# ATUC256L3U device description
Architecture: AVR32_UC3; Family: AVR UC3
Registers are 32-bit, read-write, reset 0x0 unless marked. A register's access mark holds for its fields unless they carry their own. Offsets are from the block's base; [hi:lo] are bit positions; {n}, {i} and the like mark numbered series; 'fields as' and 'values as' point back to an identical list.

## INTC — Interrupt Controller
Instances: INTC 0xffff1000
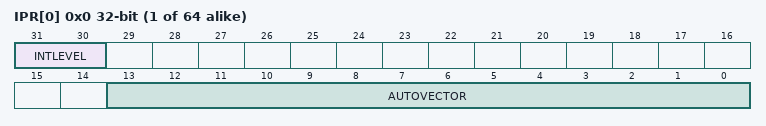
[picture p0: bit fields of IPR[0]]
{0x0+4i} IPR[{i}] (i=0..63) — Interrupt Priority Register
  [31:30] INTLEVEL — Interrupt Level
    {v}=INT{v} (v=0..3)
  [13:0] AUTOVECTOR — Handler offset
{0x100+4i} IRR[{i}] (i=0..63) ro — Interrupt Request Register
{0x200+4i} ICR[{i}] (i=0..3) ro — Interrupt Cause Register
  [5:0] CAUSE — Cause Group Number

## ABDACB — Audio Bitstream DAC
Instances: ABDACB 0xffff7400
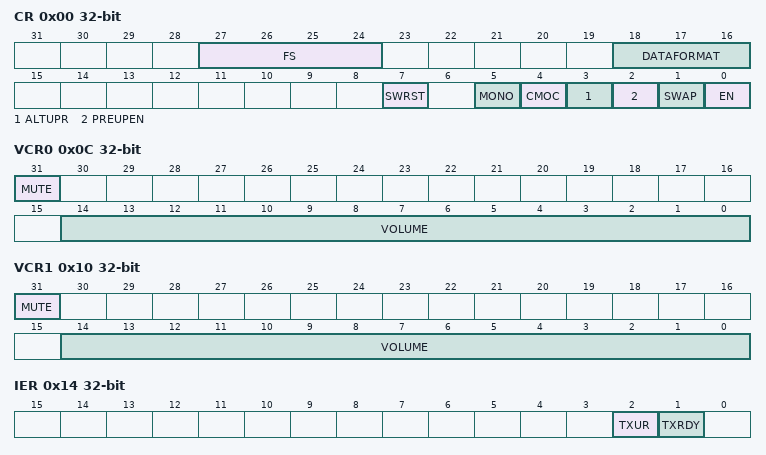
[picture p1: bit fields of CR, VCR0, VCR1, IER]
0x00 CR — Control Register
  [27:24] FS — Sampling frequency
  [18:16] DATAFORMAT — Data word format
  [7] SWRST — Software reset
  [5] MONO — Mono mode
  [4] CMOC — Common mode offset control
  [3] ALTUPR — Alternative up-sampling ratio
  [2] PREUPEN — Pre-upsampler enable
  [1] SWAP — Swap Channels
  [0] EN — Enable Audio DAC.
0x04 SDR0 — Sample Data Register 0
  [31:0] DATA
0x08 SDR1 — Sample Data Register 1
  [31:0] DATA
0x0C VCR0 — Volume Control Register 0
  [31] MUTE
  [14:0] VOLUME — Volume setting
0x10 VCR1 — Volume Control Register 1
  [31] MUTE
  [14:0] VOLUME — Volume setting
0x14 IER wo reset not defined — Interrupt Enable Register
  [2] TXUR — Underrun Interrupt Enable
  [1] TXRDY — TX Ready Interrupt Enable
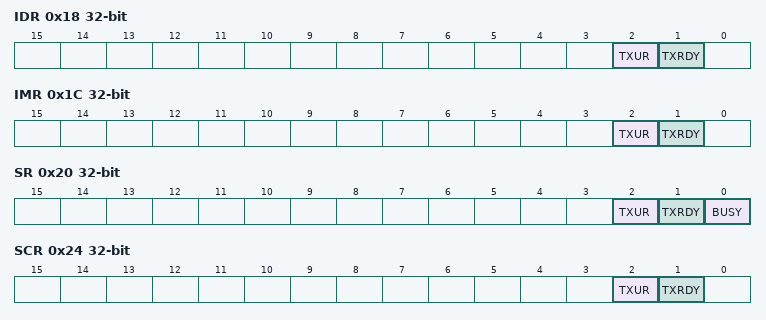
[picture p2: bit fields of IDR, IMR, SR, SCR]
0x18 IDR wo reset not defined — Interupt Disable Register
  [2] TXUR — Underrun Interrupt Disable
  [1] TXRDY — TX Ready Interrupt Disable
0x1C IMR ro — Interrupt Mask Register
  [2] TXUR — Underrun Interrupt Mask
  [1] TXRDY — TX Ready Interrupt Mask
0x20 SR ro — Status Register
  [2] TXUR — TX underrun
  [1] TXRDY — TX ready
  [0] BUSY
0x24 SCR wo reset not defined — Status Clear Register
  [2] TXUR — Underrun Interrupt Clear
  [1] TXRDY — TX Ready Interrupt Clear
0x28 PARAMETER ro
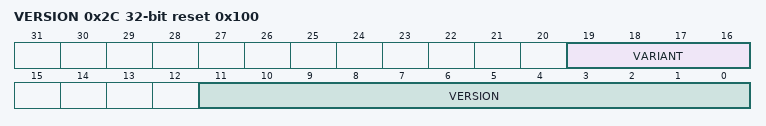
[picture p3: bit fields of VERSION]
0x2C VERSION ro reset 0x100
  [19:16] VARIANT, [11:0] VERSION

## ACIFB — Analog Comparator Interface
Instances: ACIFB 0xffff6400
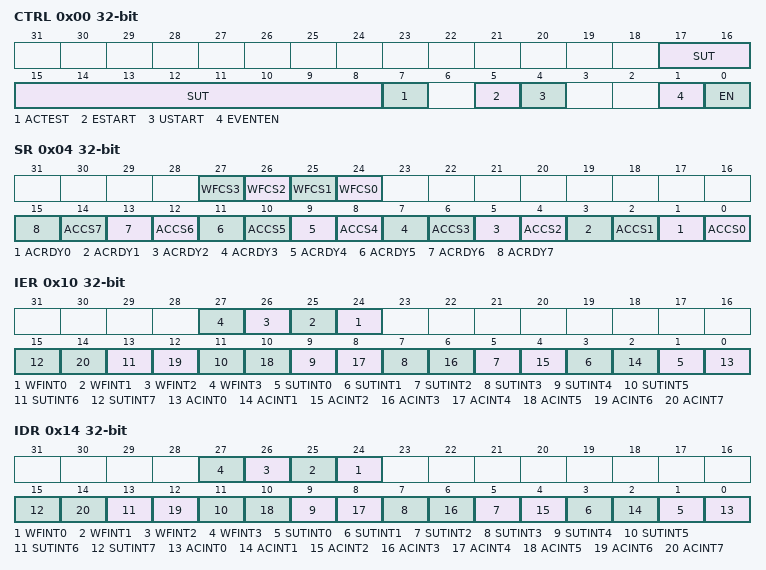
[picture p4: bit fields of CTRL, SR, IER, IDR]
0x00 CTRL — Control Register
  [17:8] SUT, [7] ACTEST, [5] ESTART, [4] USTART, [1] EVENTEN, [0] EN
0x04 SR ro — Status Register
  [n+24] WFCS{n} (n=0..3), [2n+1] ACRDY{n} (n=0..7), [2n] ACCS{n} (n=0..7)
0x10 IER wo — Interrupt Enable Register
  [n+24] WFINT{n} (n=0..3), [2n+1] SUTINT{n} (n=0..7), [2n] ACINT{n} (n=0..7)
0x14 IDR wo — Interrupt Disable Register
  fields as IER
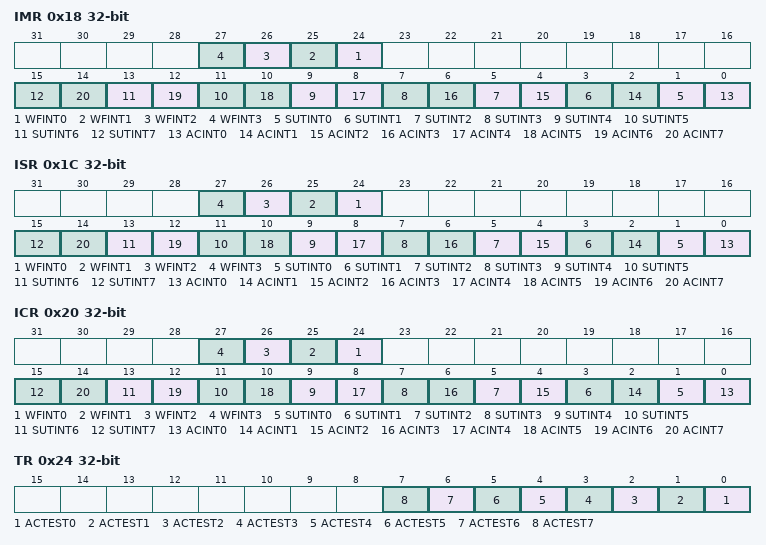
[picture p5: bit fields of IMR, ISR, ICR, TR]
0x18 IMR ro — Interrupt Mask Register
  fields as IER
0x1C ISR ro — Interrupt Status Register
  fields as IER
0x20 ICR wo — Interrupt Status Clear Register
  fields as IER
0x24 TR — Test Register
  [n] ACTEST{n} (n=0..7)
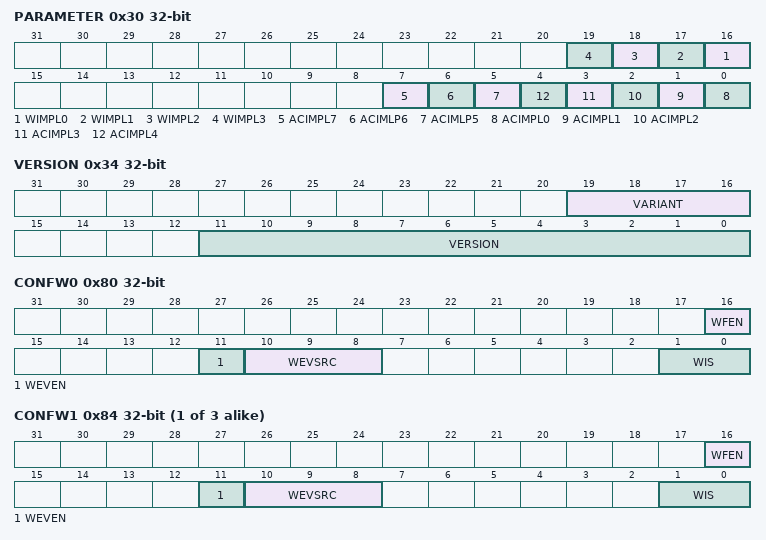
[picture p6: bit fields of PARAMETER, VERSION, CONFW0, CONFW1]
0x30 PARAMETER ro
  [n+16] WIMPL{n} (n=0..3), [7] ACIMPL7, [6] ACIMLP6, [5] ACIMLP5, [n] ACIMPL{n} (n=0..4)
0x34 VERSION ro reset not defined
  [19:16] VARIANT, [11:0] VERSION
0x80 CONFW0 — Window configuration Register
  [16] WFEN, [11] WEVEN, [10:8] WEVSRC, [1:0] WIS
{0x80+4i} CONFW{i} (i=1..3) — Window Configuration Register
  [16] WFEN, [11] WEVEN, [10:8] WEVSRC, [1:0] WIS
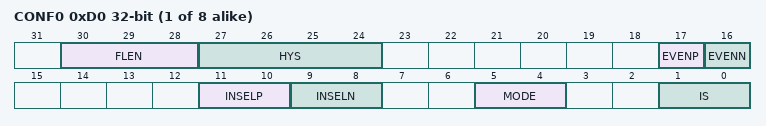
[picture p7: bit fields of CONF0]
{0xD0+4i} CONF{i} (i=0..7) — AC Configuration Register
  [30:28] FLEN, [27:24] HYS, [17] EVENP, [16] EVENN, [11:10] INSELP, [9:8] INSELN, [5:4] MODE, [1:0] IS

## ADCIFB — ADC Interface
Instances: ADCIFB 0xffff6000
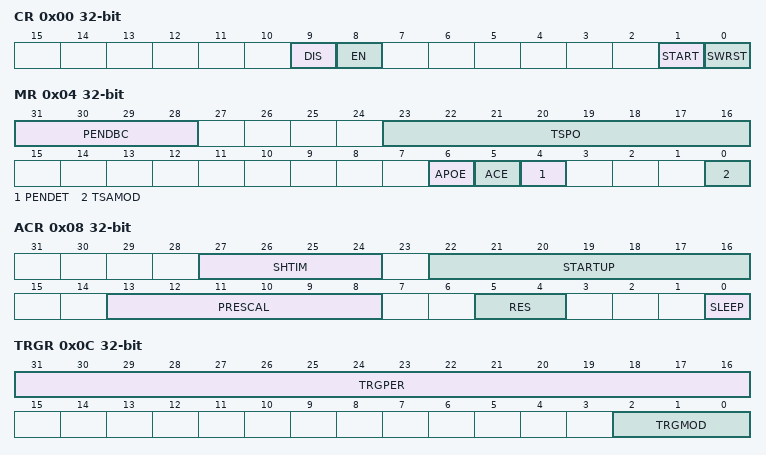
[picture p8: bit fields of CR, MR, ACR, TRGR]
0x00 CR wo reset not defined — Control Register
  [9] DIS — ADCIFB Disable
  [8] EN — ADCIFB Enable
  [1] START — Start Conversion
  [0] SWRST — Software Reset
0x04 MR — Mode Regstier
  [31:28] PENDBC — Pen Detect debouncing period
  [23:16] TSPO — Touch Screen Pin Offset
  [6] APOE — Analog Pin Output Enable
  [5] ACE — Analog Compare Enable
  [4] PENDET — Pen Detect Selection
  [0] TSAMOD — Touch Screen ADC Mode
0x08 ACR — ADC Configuration Register
  [27:24] SHTIM — Sample and Hold Time for ADC channels
  [22:16] STARTUP — Start Up Time
  [13:8] PRESCAL — Prescaler Rate Selection
  [5:4] RES — Resolution Selection
  [0] SLEEP — Sleep Mode
0x0C TRGR — Trigger Register
  [31:16] TRGPER — Trigger Period
  [2:0] TRGMOD — Trigger Mode
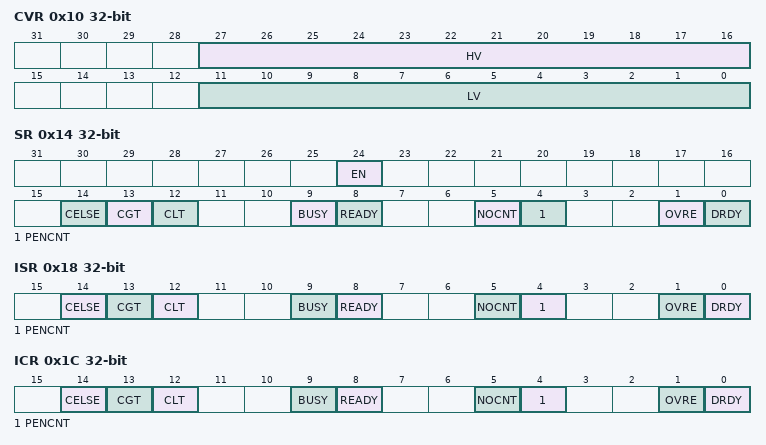
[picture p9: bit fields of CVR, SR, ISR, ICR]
0x10 CVR — Compare Value Register
  [27:16] HV — High Value
  [11:0] LV — Low Value
0x14 SR ro — Status Register
  [24] EN — Enable status
  [14] CELSE — Compare Else
  [13] CGT — Compare Greater Than
  [12] CLT — Compare Lesser Than
  [9] BUSY — Busy status
  [8] READY — Ready status
  [5] NOCNT — No Contact
  [4] PENCNT — Pen Contact
  [1] OVRE — Overrun Error
  [0] DRDY — Data Ready
0x18 ISR ro — Interrupt Status Register
  [14] CELSE — Compare Else
  [13] CGT — Compare Greater Than
  [12] CLT — Compare Lesser Than
  [9] BUSY
  [8] READY
  [5] NOCNT — No Conact
  [4] PENCNT — Pen Contact
  [1] OVRE — Overrun Error
  [0] DRDY — Data Ready
0x1C ICR wo reset not defined — Status Clear Register
  fields as ISR
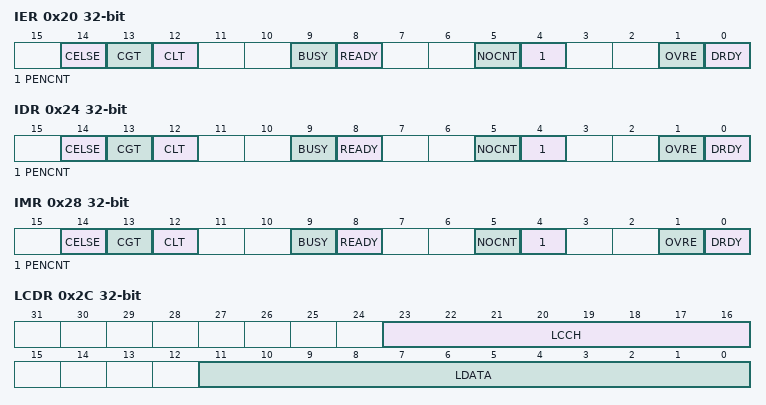
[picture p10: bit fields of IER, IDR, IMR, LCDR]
0x20 IER wo reset not defined — Interrupt Enable Register
  fields as ISR
0x24 IDR wo reset not defined — Interrupt Disable Register
  fields as ISR
0x28 IMR ro — Interrupt Mask Register
  fields as ISR
0x2C LCDR ro — Last Converted Data Register
  [23:16] LCCH — Last Converted Channel
  [11:0] LDATA — Last Converted Data Register
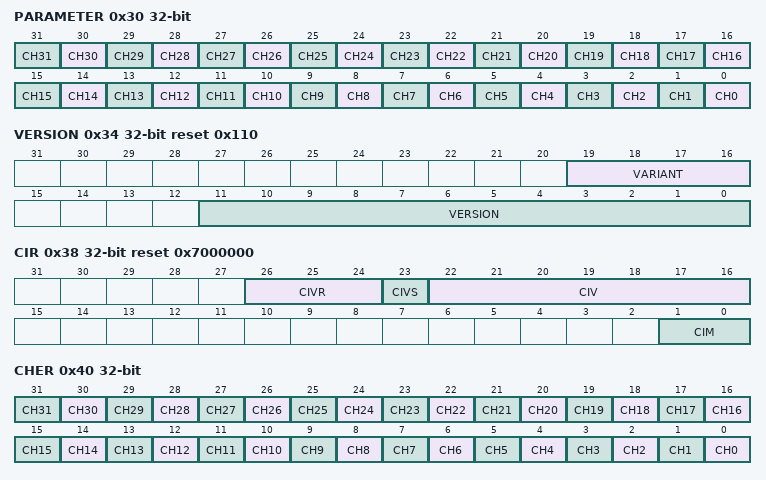
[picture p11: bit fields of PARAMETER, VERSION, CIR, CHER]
0x30 PARAMETER ro reset not defined
  [n] CH{n} (n=0..31) — Indicates if the channel is implemented or not
0x34 VERSION ro reset 0x110
  [19:16] VARIANT — Variant number
  [11:0] VERSION — Version number
0x38 CIR reset 0x7000000 — Current Injection Register
  [26:24] CIVR — Currecnt Injection Value Range
  [23] CIVS — Currecnt Injection Value Sign
  [22:16] CIV — Current Injection Value
  [1:0] CIM — Current Injection Mode
0x40 CHER wo reset not defined — Channel Enable Register
  [n] CH{n} (n=0..31)
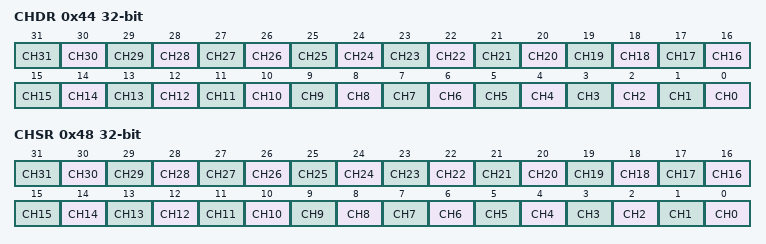
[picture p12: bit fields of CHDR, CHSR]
0x44 CHDR wo reset not defined — Channel Disable Register
  [n] CH{n} (n=0..31)
0x48 CHSR ro — Channel Status Register
  [n] CH{n} (n=0..31)
